# AT90PWM3 register map
Vendor: Atmel; File version: 1.0
CPU: other r0p0, little endian, no MPU, no FPU, 4 interrupt priority bits
Registers are 8-bit, read-write, reset 0x0 unless marked. A register's access mark holds for its fields unless they carry their own. Offsets are from the block's base; [hi:lo] are bit positions; {n}, {i} and the like mark numbered series; 'fields as' and 'values as' point back to an identical list.

## EEPROM
Base 0x0080003F
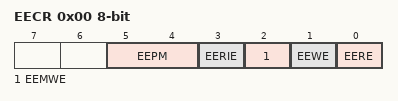
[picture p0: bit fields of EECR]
0x00 EECR — EEPROM Control Register
  [5:4] EEPM — EEPROM Programming Mode
  [3] EERIE — EEPROM Ready Interrupt Enable
  [2] EEMWE — EEPROM Master Write Enable
  [1] EEWE — EEPROM Write Enable
  [0] EERE — EEPROM Read Enable
0x01 EEDR — EEPROM Data Register
  [7:0] EEDR — EEPROM Data Bits
0x02 EEAR 16-bit (reset mask 0xFF) — EEPROM Read/Write Access Bytes
  [11:0] EEAR — EEPROM Address bytes

## EUSART — Extended USART
Base 0x008000C8
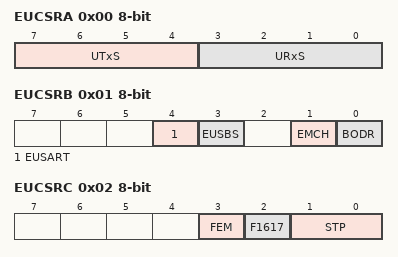
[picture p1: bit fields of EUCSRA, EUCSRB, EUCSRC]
0x00 EUCSRA — EUSART Control and Status Register A
  [7:4] UTxS — EUSART Control and Status Register A Bits
    {v}={v+5}_BIT (v=0..3); 7=9_BIT; {v}={v+5}_BIT (v=8..11); 15=17_BIT
  [3:0] URxS — EUSART Control and Status Register A Bits
    {v}={v+5}_BIT (v=0..3); 7=9_BIT; {v}={v+5}_BIT (v=8..11); 14=16_OR_17; 15=17_BIT
0x01 EUCSRB — EUSART Control Register B
  [4] EUSART — EUSART Enable Bit
  [3] EUSBS — EUSBS Enable Bit
  [1] EMCH — Manchester Mode Bit
  [0] BODR — Order Bit
0x02 EUCSRC — EUSART Status Register C (read-only for debugger)
  [3] FEM — Frame Error Manchester Bit
  [2] F1617 — F1617 Bit
  [1:0] STP — Stop Bits
0x04 MUBRR 16-bit (reset mask 0xFF) — Manchester Receiver Baud Rate Register
  [15:0] MUBRR — Manchester Receiver Baud Rate Register Bits
0x06 EUDR — EUSART I/O Data Register (write-only for debugger)
  [7:0] EUDR — EUSART Extended data bits

## EXINT — External Interrupts
Base 0x0080003C
0x00 EIFR — External Interrupt Flag Register (read-only for debugger)
  [3:0] INTF — External Interrupt Flags
0x01 EIMSK — External Interrupt Mask Register
  [3:0] INT — External Interrupt Request Enable
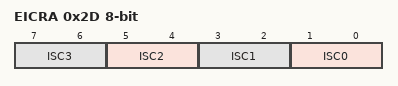
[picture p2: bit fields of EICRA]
0x2D EICRA — External Interrupt Control Register A
  [all] fields
    0=LOW_LEVEL_OF_INTX; 1=ANY_LOGICAL_CHANGE_OF_INTX; 2=FALLING_EDGE_OF_INTX; 3=RISING_EDGE_OF_INTX
  [2n+1:2n] ISC{n} (n=0..3) — External Interrupt Sense Control Bit

## LOCKBIT — Lockbits
Base 0x00800000
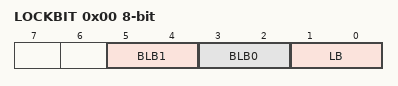
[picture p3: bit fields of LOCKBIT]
0x00 LOCKBIT
  [5:4] BLB1 — Boot Loader Protection Mode
    0=LPM_SPM_DISABLE (LPM and SPM prohibited in Boot Section); 1=LPM_DISABLE (LPM prohibited in Boot Section); 2=SPM_DISABLE (SPM prohibited in Boot Section); 3=NO_LOCK (No lock on SPM and LPM in Boot Section)
  [3:2] BLB0 — Boot Loader Protection Mode
    0=LPM_SPM_DISABLE (LPM and SPM prohibited in Application Section); 1=LPM_DISABLE (LPM prohibited in Application Section); 2=SPM_DISABLE (SPM prohibited in Application Section); 3=NO_LOCK (No lock on SPM and LPM in Application Section)
  [1:0] LB — Memory Lock
    0=PROG_VER_DISABLED (Further programming and verification disabled); 2=PROG_DISABLED (Further programming disabled); 3=NO_LOCK (No memory lock features enabled)

## PORTB — I/O Port
Base 0x00800023
0x00 PINB — Port B Input Pins (read-only for debugger)
0x01 DDRB — Port B Data Direction Register
0x02 PORTB — Port B Data Register

## PORTC — I/O Port
Base 0x00800026
0x00 PINC — Port C Input Pins (read-only for debugger)
0x01 DDRC — Port C Data Direction Register
0x02 PORTC — Port C Data Register

## PORTD — I/O Port
Base 0x00800029
0x00 PIND — Port D Input Pins (read-only for debugger)
0x01 DDRD — Port D Data Direction Register
0x02 PORTD — Port D Data Register

## PORTE — I/O Port
Base 0x0080002C
0x00 PINE — Port E Input Pins (read-only for debugger)
0x01 DDRE — Port E Data Direction Register
0x02 PORTE — Port E Data Register

## PSC0 — Power Stage Controller
Base 0x008000A0
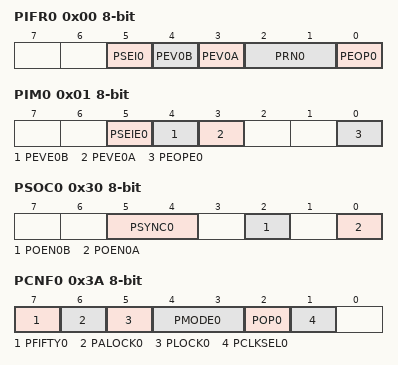
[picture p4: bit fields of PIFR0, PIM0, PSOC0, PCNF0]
0x00 PIFR0 — PSC0 Interrupt Flag Register
  [5] PSEI0 — PSC 0 Synchro Error Interrupt
  [4] PEV0B — External Event B Interrupt
  [3] PEV0A — External Event A Interrupt
  [2:1] PRN0 — Ramp Number
    {v}={v+1} (v=0..3)
  [0] PEOP0 — End of PSC0 Interrupt
0x01 PIM0 — PSC0 Interrupt Mask Register
  [5] PSEIE0 — PSC 0 Synchro Error Interrupt Enable
  [4] PEVE0B — External Event B Interrupt Enable
  [3] PEVE0A — External Event A Interrupt Enable
  [0] PEOPE0 — End of Cycle Interrupt Enable
0x30 PSOC0 — PSC0 Synchro and Output Configuration
  [5:4] PSYNC0 — Synchronization Out for ADC Selection
    0=SEND_SIGNAL_ON_LEADING_EDGE_OF_PSCOUTN0; 1=SEND_SIGNAL_ON_TRAILING_EDGE_OF_PSCOUTN0; 2=SEND_SIGNAL_ON_LEADING_EDGE_OF_PSCOUTN1; 3=SEND_SIGNAL_ON_TRAILING_EDGE_OF_PSCOUTN1
  [2] POEN0B — PSCOUT01 Output Enable
  [0] POEN0A — PSCOUT00 Output Enable
0x32 OCR0SA 16-bit (reset mask 0xFF) — Output Compare 0 SA Register
  [11:0] OCR0SA — Output Compare SA
0x34 OCR0RA 16-bit (reset mask 0xFF) — Output Compare 0 RA Register
  [11:0] OCR0RA — Output Compare RA
0x36 OCR0SB 16-bit (reset mask 0xFF) — Output Compare 0 SB Register
  [11:0] OCR0SB — Output Compare SB
0x38 OCR0RB 16-bit (reset mask 0xFF) — Output Compare 0 RB Register
  [15:0] OCR0RB — Output Compare RB
0x3A PCNF0 — PSC 0 Configuration Register
  [7] PFIFTY0 — PSC 0 Fifty
  [6] PALOCK0 — PSC 0 Autolock
  [5] PLOCK0 — PSC 0 Lock
  [4:3] PMODE0 — PSC 0 Mode
    0=ONE_RAMP_MODE; 1=TWO_RAMP_MODE; 2=FOUR_RAMP_MODE; 3=CENTER_ALIGNED_MODE
  [2] POP0 — PSC 0 Output Polarity
  [1] PCLKSEL0 — PSC 0 Input Clock Select
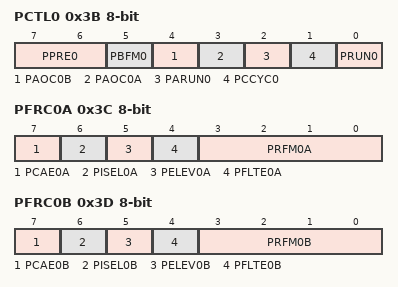
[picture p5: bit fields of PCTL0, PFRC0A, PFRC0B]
0x3B PCTL0 — PSC 0 Control Register
  [7:6] PPRE0 — PSC 0 Prescaler Selects
    0=NO_DIVIDER_ON_PSC_INPUT_CLOCK; 1=DIVIDE_THE_PSC_INPUT_CLOCK_BY_4; 2=DIVIDE_THE_PSC_INPUT_CLOCK_BY_16; 3=DIVIDE_THE_PSC_INPUT_CLOCK_BY_64
  [5] PBFM0 — PSC 0 Balance Flank Width Modulation
  [4] PAOC0B — PSC 0 Asynchronous Output Control B
  [3] PAOC0A — PSC 0 Asynchronous Output Control A
  [2] PARUN0 — PSC0 Auto Run
  [1] PCCYC0 — PSC0 Complete Cycle
  [0] PRUN0 — PSC 0 Run
0x3C PFRC0A — PSC 0 Input A Control
  [7] PCAE0A — PSC 0 Capture Enable Input Part A
  [6] PISEL0A — PSC 0 Input Select for Part A
  [5] PELEV0A — PSC 0 Edge Level Selector on Input Part A
  [4] PFLTE0A — PSC 0 Filter Enable on Input Part A
  [3:0] PRFM0A — PSC 0 Retrigger and Fault Mode for Part A
    0=NO_ACTION_PSC_INPUT_IS_IGNORED; 2=STOP_SIGNAL_EXECUTE_OPPOSITE_DEAD_TIME_AND_WAIT; 3=STOP_SIGNAL_EXECUTE_OPPOSITE_WHILE_FAULT_ACTIVE; 4=DEACTIVATE_OUTPUTS_WITHOUT_CHANGING_TIMING; 5=STOP_SIGNAL_AND_INSERT_DEAD_TIME; 6=STOP_SIGNAL_JUMP_TO_OPPOSITE_DEAD_TIME_AND_WAIT; 7=HALT_PSC_AND_WAIT_FOR_SOFTWARE_ACTION; 8=EDGE_RETRIGGER_PSC; 9=FIXED_FREQUENCY_EDGE_RETRIGGER_PSC; 14=FIXED_FREQUENCY_EDGE_RETRIGGER_PSC_AND_DISACTIVATE_OUTPUT (Fixed Frequency Edge Retrigger PSC and Deactivate Output); 15=RESERVED_DO_NOT_USE
0x3D PFRC0B — PSC 0 Input B Control
  [7] PCAE0B — PSC 0 Capture Enable Input Part B
  [6] PISEL0B — PSC 0 Input Select for Part B
  [5] PELEV0B — PSC 0 Edge Level Selector on Input Part B
  [4] PFLTE0B — PSC 0 Filter Enable on Input Part B
  [3:0] PRFM0B — PSC 0 Retrigger and Fault Mode for Part B
    values as PFRC0A.PRFM0A
0x3E PICR0 16-bit (reset mask 0xFF) — PSC 0 Input Capture Register
  [11:0] PICR0 — PSC 0 Input Capture Bytes
